# ATxmega128A1U device description
Architecture: AVR8_XMEGA; Family: AVR XMEGA
Registers are 8-bit, access not given, no defined reset value unless marked. A register's access mark holds for its fields unless they carry their own. Offsets are from the block's base; [hi:lo] are bit positions; lines under a group give offsets from that group; {n}, {i} and the like mark numbered series; 'fields as' and 'values as' point back to an identical list.

## AC — Analog Comparator
Instances: ACA 0x0380, ACB 0x0390
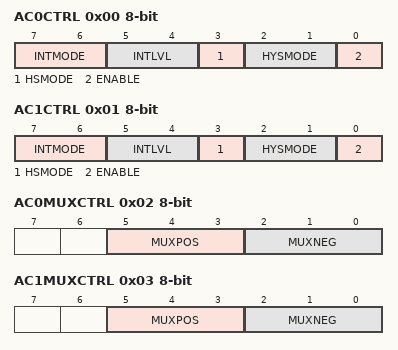
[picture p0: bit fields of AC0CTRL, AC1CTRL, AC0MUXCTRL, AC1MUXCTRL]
0x00 AC0CTRL — Analog Comparator 0 Control
  [7:6] INTMODE — Interrupt Mode
    0=BOTHEDGES (Interrupt on both edges); 2=FALLING (Interrupt on falling edge); 3=RISING (Interrupt on rising edge)
  [5:4] INTLVL — Interrupt Level
    0=OFF (Interrupt disabled); 1=LO (Low level); 2=MED (Medium level); 3=HI (High level)
  [3] HSMODE — High-speed Mode
  [2:1] HYSMODE — Hysteresis Mode
    0=NO (No hysteresis); 1=SMALL (Small hysteresis); 2=LARGE (Large hysteresis)
  [0] ENABLE
0x01 AC1CTRL — Analog Comparator 1 Control
  fields as AC0CTRL
0x02 AC0MUXCTRL — Analog Comparator 0 MUX Control
  [5:3] MUXPOS — MUX Positive Input
    {v}=PIN{v} (v=0..6); 7=DAC (DAC output)
  [2:0] MUXNEG — MUX Negative Input
    0=PIN0; 1=PIN1; 2=PIN3; 3=PIN5; 4=PIN7; 5=DAC (DAC output); 6=BANDGAP (Bandgap Reference); 7=SCALER (Internal voltage scaler)
0x03 AC1MUXCTRL — Analog Comparator 1 MUX Control
  fields as AC0MUXCTRL
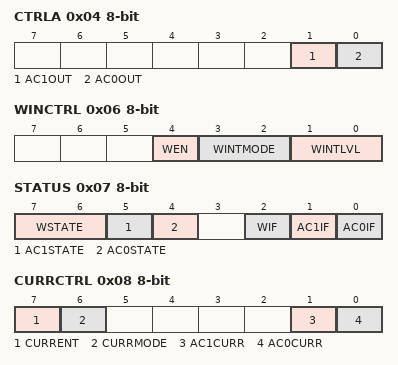
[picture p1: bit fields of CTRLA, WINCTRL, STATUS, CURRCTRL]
0x04 CTRLA — Control Register A
  [1] AC1OUT — Analog Comparator 1 Output Enable
  [0] AC0OUT — Analog Comparator 0 Output Enable
0x05 CTRLB — Control Register B
  [5:0] SCALEFAC — VCC Voltage Scaler Factor
0x06 WINCTRL — Window Mode Control
  [4] WEN — Window Mode Enable
  [3:2] WINTMODE — Window Interrupt Mode
    0=ABOVE (Interrupt on above window); 1=INSIDE (Interrupt on inside window); 2=BELOW (Interrupt on below window); 3=OUTSIDE (Interrupt on outside window)
  [1:0] WINTLVL — Window Interrupt Level
    0=OFF (Interrupt disabled); 1=LO (Low priority); 2=MED (Medium priority); 3=HI (High priority)
0x07 STATUS
  [7:6] WSTATE — Window Mode State
    0=ABOVE (Signal above window); 1=INSIDE (Signal inside window); 2=BELOW (Signal below window)
  [5] AC1STATE — Analog Comparator 1 State
  [4] AC0STATE — Analog Comparator 0 State
  [2] WIF — Window Mode Interrupt Flag
  [1] AC1IF — Analog Comparator 1 Interrupt Flag
  [0] AC0IF — Analog Comparator 0 Interrupt Flag
0x08 CURRCTRL — Current Source Control
  [7] CURRENT — Current Source Enable
  [6] CURRMODE — Current Mode
  [1] AC1CURR — AC1 Current Source Output Enable
  [0] AC0CURR — AC0 Current Source Output Enable
0x09 CURRCALIB — Current Source Calibration
  [3:0] CALIB

## RTC — Real-Time Counter
Instances: RTC 0x0400
0x00 CTRL — Control Register
  [2:0] PRESCALER — Prescaling Factor
    0=OFF (RTC Off); 1=DIV1 (RTC Clock); 2=DIV2 (RTC Clock / 2); 3=DIV8 (RTC Clock / 8); 4=DIV16 (RTC Clock / 16); 5=DIV64 (RTC Clock / 64); 6=DIV256 (RTC Clock / 256); 7=DIV1024 (RTC Clock / 1024)
0x01 STATUS
  [0] SYNCBUSY — Synchronization Busy Flag
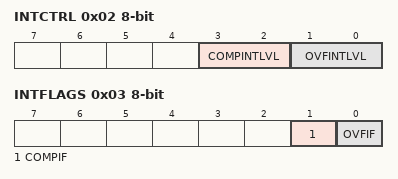
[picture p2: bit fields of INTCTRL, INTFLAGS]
0x02 INTCTRL — Interrupt Control Register
  [3:2] COMPINTLVL — Compare Match Interrupt Level
    0=OFF (Interrupt Disabled); 1=LO (Low Level); 2=MED (Medium Level); 3=HI (High Level)
  [1:0] OVFINTLVL — Overflow Interrupt Level
    values as COMPINTLVL
0x03 INTFLAGS — Interrupt Flags
  [1] COMPIF — Compare Match Interrupt Flag
  [0] OVFIF — Overflow Interrupt Flag
0x04 TEMP — Temporary register
0x08 CNT 16-bit — Count Register
0x0A PER 16-bit — Period Register
0x0C COMP 16-bit — Compare Register

## EBI — External Bus Interface
Instances: EBI 0x0440
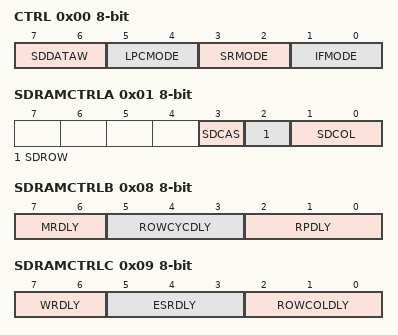
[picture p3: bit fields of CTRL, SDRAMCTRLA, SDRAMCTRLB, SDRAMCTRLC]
0x00 CTRL — Control
  [7:6] SDDATAW — SDRAM Data Width Setting
    0=4BIT (4-bit data bus); 1=8BIT (8-bit data bus)
  [5:4] LPCMODE — SRAM LPC Mode
    0=ALE1 (Data muxed with addr byte 0); 2=ALE12 (Data muxed with addr byte 0 and 1)
  [3:2] SRMODE — SRAM Mode
    0=ALE1 (Addr byte 0 muxed with 1); 1=ALE2 (Addr byte 0 muxed with 2); 2=ALE12 (Addr byte 0 muxed with 1 and 2); 3=NOALE (No addr muxing)
  [1:0] IFMODE — Interface Mode
    0=DISABLED (EBI Disabled); 1=3PORT (3-port mode); 2=4PORT (4-port mode); 3=2PORT (2-port mode)
0x01 SDRAMCTRLA — SDRAM Control Register A
  [3] SDCAS — SDRAM CAS Latency Setting
  [2] SDROW — SDRAM ROW Bits Setting
  [1:0] SDCOL — SDRAM Column Bits Setting
    {v}={v+8}BIT ({v+8} column bits) (v=0..3)
0x04 REFRESH 16-bit — SDRAM Refresh Period
0x06 INITDLY 16-bit — SDRAM Initialization Delay
0x08 SDRAMCTRLB — SDRAM Control Register B
  [7:6] MRDLY — SDRAM Mode Register Delay
    0=0CLK (0 cycles); 1=1CLK (1 cycle); 2=2CLK (2 cycles); 3=3CLK (3 cycles)
  [5:3] ROWCYCDLY — SDRAM Row Cycle Delay
    0=0CLK (0 cycles); 1=1CLK (1 cycle); {v}={v}CLK ({v} cycles) (v=2..7)
  [2:0] RPDLY — SDRAM Row-to-Precharge Delay
    values as ROWCYCDLY
0x09 SDRAMCTRLC — SDRAM Control Register C
  [7:6] WRDLY — SDRAM Write Recovery Delay
    values as SDRAMCTRLB.MRDLY
  [5:3] ESRDLY — SDRAM Exit-Self-refresh-to-Active Delay
    values as SDRAMCTRLB.ROWCYCDLY
  [2:0] ROWCOLDLY — SDRAM Row-to-Column Delay
    values as SDRAMCTRLB.ROWCYCDLY
{0x10+4i} CS{i} group (i=0..3) — Chip Select {i}
  0x00 CTRLA — Chip Select Control Register A
    [6:2] ASIZE — Address Size
      0=256B (256 bytes); 1=512B (512 bytes); 2=1KB (1K bytes); 3=2KB (2K bytes); 4=4KB (4K bytes); 5=8KB (8K bytes); 6=16KB (16K bytes); 7=32KB (32K bytes); 8=64KB (64K bytes); 9=128KB (128K bytes); 10=256KB (256K bytes); 11=512KB (512K bytes); 12=1MB (1M bytes); 13=2MB (2M bytes); 14=4MB (4M bytes); 15=8MB (8M bytes); 16=16M (16M bytes)
    [6:2] ASPACE — Legacy name: Address Space
      values as ASIZE
    [1:0] MODE — Memory Mode
      0=DISABLED (Chip Select Disabled); 1=SRAM (Chip Select in SRAM mode); 2=LPC (Chip Select in SRAM LPC mode); 3=SDRAM (Chip Select in SDRAM mode)
  0x01 CTRLB — Chip Select Control Register B
    [7] SDINITDONE — SDRAM Initialization Done
    [2] SDSREN — SDRAM Self-refresh Enable
    [2:0] SRWS — SRAM Wait State Cycles
      values as SDRAMCTRLB.ROWCYCDLY
    [1:0] SDMODE — SDRAM Mode
      0=NORMAL (Normal mode); 1=LOAD (Load Mode Register command mode)
  0x02 BASEADDR 16-bit — Base Address
    [15:4] BASEADDR — Chip Select Base Address
